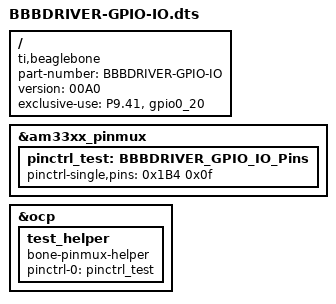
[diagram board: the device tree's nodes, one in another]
/dts-v1/;
/plugin/;

/{
       compatible = "ti,beaglebone", "ti,beaglebone-black";
       part-number = "BBBDRIVER-GPIO-IO";
       version = "00A0";

    /* state the resources this cape uses */
        exclusive-use = 
            /* the pin header uses */
            "P9.41",        /* gpio */
            /* the hardware IP uses */
            "gpio0_20";
       fragment@0 {
             target = <&am33xx_pinmux>;
            
             __overlay__ {
                  pinctrl_test: BBBDRIVER_GPIO_IO_Pins {
			pinctrl-single,pins = <
                0x1B4 0x0f  /* P9_41 */
                  
			>;
		  };
             };
       };

       fragment@1 {
		target = <&ocp>;
		__overlay__ {
			test_helper {
				compatible = "bone-pinmux-helper";
				status = "okay";
				pinctrl-names = "default";
				pinctrl-0 = <&pinctrl_test>;
				
			};
		};
	};
};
